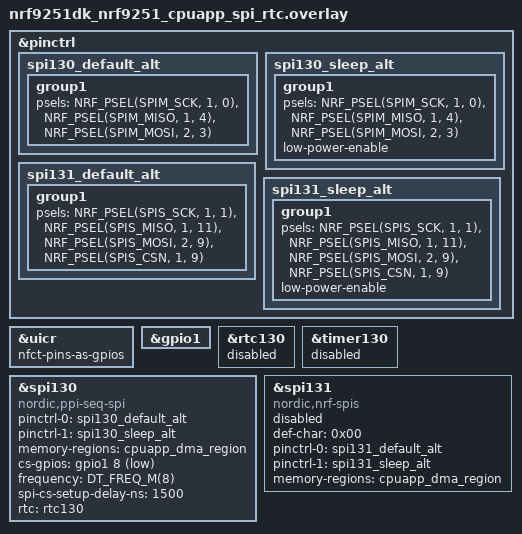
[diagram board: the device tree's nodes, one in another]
/*
 * Copyright (c) 2026 Nordic Semiconductor ASA
 *
 * SPDX-License-Identifier: LicenseRef-Nordic-5-Clause
 */

/* Test requires loopbacks:
 * - between P1.00 and P1.01
 * - between P1.04 and P1.11
 * - between P2.03 and P2.09
 * - between P1.08 and P1.09
 */

&pinctrl {
	spi130_default_alt: spi130_default_alt {
		group1 {
			psels = <NRF_PSEL(SPIM_SCK, 1, 0)>,
				<NRF_PSEL(SPIM_MISO, 1, 4)>,
				<NRF_PSEL(SPIM_MOSI, 2, 3)>;
		};
	};

	spi130_sleep_alt: spi130_sleep_alt {
		group1 {
			psels = <NRF_PSEL(SPIM_SCK, 1, 0)>,
				<NRF_PSEL(SPIM_MISO, 1, 4)>,
				<NRF_PSEL(SPIM_MOSI, 2, 3)>;
			low-power-enable;
		};
	};

	spi131_default_alt: spi131_default_alt {
		group1 {
			psels = <NRF_PSEL(SPIS_SCK, 1, 1)>,
				<NRF_PSEL(SPIS_MISO, 1, 11)>,
				<NRF_PSEL(SPIS_MOSI, 2, 9)>,
				<NRF_PSEL(SPIS_CSN, 1, 9)>;
		};
	};

	spi131_sleep_alt: spi131_sleep_alt {
		group1 {
			psels = <NRF_PSEL(SPIS_SCK, 1, 1)>,
				<NRF_PSEL(SPIS_MISO, 1, 11)>,
				<NRF_PSEL(SPIS_MOSI, 2, 9)>,
				<NRF_PSEL(SPIS_CSN, 1, 9)>;
			low-power-enable;
		};
	};
};

&uicr {
	nfct-pins-as-gpios;
};

&gpio1 {
	status = "okay";
};

/* Used as trigger by the PPI sequencer. */
&rtc130 {
	status = "reserved";
};

test_timer: &timer130 {
	status = "reserved";
};

dut: &spi130 {
	compatible = "nordic,ppi-seq-spi";
	status = "okay";
	pinctrl-0 = <&spi130_default_alt>;
	pinctrl-1 = <&spi130_sleep_alt>;
	pinctrl-names = "default", "sleep";
	memory-regions = <&cpuapp_dma_region>;
	cs-gpios = <&gpio1 8 GPIO_ACTIVE_LOW>;
	frequency = <DT_FREQ_M(8)>;
	spi-cs-setup-delay-ns = <1500>;
	rtc = <&rtc130>;
};

tester: &spi131 {
	compatible = "nordic,nrf-spis";
	status = "reserved";
	def-char = <0x00>;
	pinctrl-0 = <&spi131_default_alt>;
	pinctrl-1 = <&spi131_sleep_alt>;
	pinctrl-names = "default", "sleep";
	memory-regions = <&cpuapp_dma_region>;
	/delete-property/ rx-delay-supported;
	/delete-property/ rx-delay;
};
